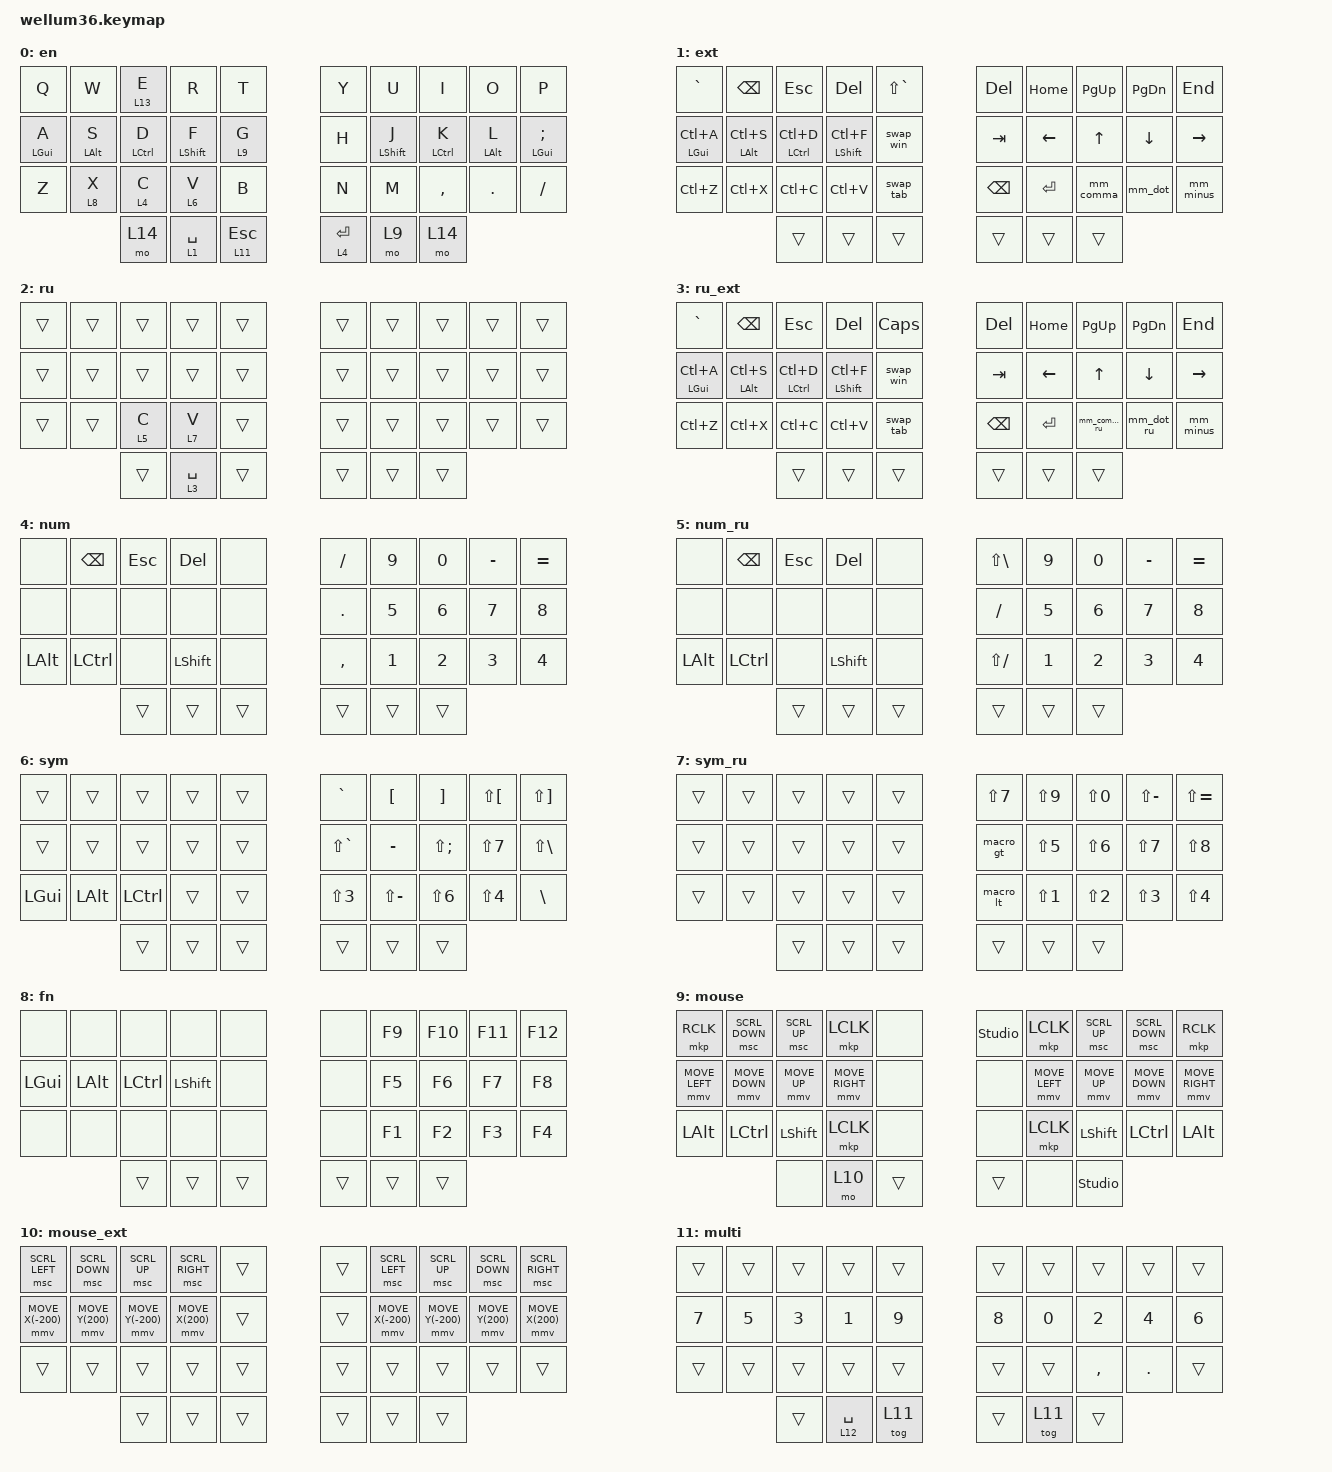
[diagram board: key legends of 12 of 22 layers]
#define ZMK_POINTING_DEFAULT_MOVE_VAL 1200  // default: 600
#define ZMK_POINTING_DEFAULT_SCRL_VAL 20    // default: 10

#include <behaviors/num_word.dtsi>
#include <behaviors.dtsi>
#include <dt-bindings/zmk/outputs.h>
#include <dt-bindings/zmk/keys.h>
#include <dt-bindings/zmk/bt.h>
#include <dt-bindings/zmk/pointing.h>

#include <dt-bindings/zmk/ext_power.h>

#define _ &kp
#define ___ &none
#define ______ &trans

#define DEF 0
#define GAM 1
#define GFN 2
#define NAV 3
#define SYM 4
#define NUM 5
#define CMD 6

#define MEH(key) LS(LC(LA(key)))

//#define SQT GRAVE
//#define DQT LS(GRAVE)
#define GRV RA(GRAVE)
#define PIP LS(BSLH)
#define BSL RA(BSLH)
#define NBSP RA(SPACE)

#define NSPC LC(LG(RIGHT))
#define PSPC LC(LG(LEFT))

// custom implementation of modified callum-mods,
// which can be released on second keypress
// and also work with swapper and/or tabber

#define PARAM_1 0
#define PARAM_2 0

#define MACRO(NAME, COMPATIBLE, BINDING_CELLS, BINDINGS) \
    NAME: NAME { \
        compatible = COMPATIBLE; \
        #binding-cells = <BINDING_CELLS>; \
        wait-ms = <0>; \
        tap-ms = <0>; \
        bindings = \
            <BINDINGS>; \
    };

#define MACRO_NO_PARAM(NAME, BINDINGS)  MACRO(NAME, "zmk,behavior-macro"          , 0, BINDINGS)
#define MACRO_ONE_PARAM(NAME, BINDINGS) MACRO(NAME, "zmk,behavior-macro-one-param", 1, BINDINGS)
#define MACRO_TWO_PARAM(NAME, BINDINGS) MACRO(NAME, "zmk,behavior-macro-two-param", 2, BINDINGS)

#define MAX_TIMER __UINT32_MAX__ // around 50 days

#define STICKY_FOREVER(NAME, BIND) \
    NAME: NAME { \
        compatible = "zmk,behavior-sticky-key"; \
        #binding-cells = <1>; \
        bindings = <BIND>; \
        release-after-ms = <MAX_TIMER>; \
        ignore-modifiers; \
    };

#define MODMORPH(NAME, NORMAL, MORPHED, MODS, KEEP_MODS) \
    NAME: NAME { \
        compatible = "zmk,behavior-mod-morph"; \
        #binding-cells = <0>; \
        bindings = <NORMAL>, <MORPHED>; \
        mods = <(MODS)>; \
        keep-mods = <(KEEP_MODS)>; \
    };

&sk {
        release-after-ms = <60000>;
};

/ {
    behaviors {
        MACRO_ONE_PARAM(
            m_release_key_twice,
            &macro_release
                &macro_param_1to1 &kp PARAM_1
                &macro_param_1to1 &kp PARAM_1
        )


        MACRO_ONE_PARAM(
            m_press_key_twice,
            &macro_press
                &macro_param_1to1 &kp PARAM_1
                &macro_param_1to1 &kp PARAM_1
            &macro_pause_for_release
            &macro_tap
                &m_release_key_twice PARAM_1
        )

        STICKY_FOREVER(sticky_forever, &m_press_key_twice)

        MODMORPH(
            cm_gui,
            &sticky_forever LGUI,
            &m_release_key_twice LGUI,
            MOD_LGUI,
            MOD_LGUI
        )

        MODMORPH(
            cm_alt,
            &sticky_forever LALT,
            &m_release_key_twice LALT,
            MOD_LALT,
            MOD_LALT
        )

        MODMORPH(
            cm_ctrl,
            &sticky_forever LCTRL,
            &m_release_key_twice LCTRL,
            MOD_LCTL,
            MOD_LCTL
        )

        MODMORPH(
            cm_sft,
            &sticky_forever LSHIFT,
            &m_release_key_twice LSHIFT,
            MOD_LSFT,
            MOD_LSFT
        )

        MACRO_TWO_PARAM(
            m_hold_mod_press_key,
            &macro_press
                &macro_param_1to1 &kp PARAM_1
            &macro_tap
                &macro_param_2to1 &kp PARAM_2
        )

        MODMORPH(
            tabber,
            &m_hold_mod_press_key LCTRL TAB,
            &kp TAB,
            MOD_LCTL,
            MOD_LCTL
        )

        MODMORPH(
            swapper_win,
            &m_hold_mod_press_key LALT TAB,
            &kp TAB,
            MOD_LALT,
            MOD_LALT
        )

        MODMORPH(
            swapper_mac,
            &m_hold_mod_press_key LGUI TAB,
            &kp TAB,
            MOD_LGUI,
            MOD_LGUI
        )

        MACRO_ONE_PARAM(
            la,
            &macro_tap
                &kp 0 // do nothing, fire all sticky keys
            &macro_press
                &macro_param_1to1 &mo PARAM_1
            &macro_pause_for_release
            &macro_release
                &macro_param_1to1 &mo PARAM_1
                &kp LSHFT
                &kp LCTRL
                &kp LALT
                &kp LGUI
        )

        tp: tap_preferred {
            compatible = "zmk,behavior-hold-tap";
            label = "TAP_PREFERRED";
            #binding-cells = <2>;
            tapping-term-ms = <150>;
            quick-tap-ms = <0>;
            flavor = "tap-preferred";
            bindings = <&kp>, <&kp>;
        };

        hml: home_row_mod_left {
            compatible = "zmk,behavior-hold-tap";
            #binding-cells = <2>;
            flavor = "balanced";
            require-prior-idle-ms = <150>;
            tapping-term-ms = <280>;
            quick-tap-ms = <175>;
            bindings = <&kp>, <&kp>;

            hold-trigger-key-positions = <5 6 7 8 9 9 15 16 18 19 26 27 28 29 35 36 37 17 5 6 7 8 9 15 16 17 18 19 25 26 27 28 29 32 33>;
            hold-trigger-on-release;
        };

        hmr: home_row_mod_right {
            compatible = "zmk,behavior-hold-tap";
            #binding-cells = <2>;
            flavor = "balanced";
            require-prior-idle-ms = <150>;
            tapping-term-ms = <280>;
            quick-tap-ms = <175>;
            bindings = <&kp>, <&kp>;

            hold-trigger-key-positions = <20 21 0 10 22 11 1 2 12 23 3 4 13 14 24 24 34 30 31>;
            hold-trigger-on-release;
        };

        num_word: num_word {
            compatible = "zmk,behavior-auto-layer";
            #binding-cells = <1>;
            continue-list = <BSPC DEL DOT COMMA PLUS MINUS STAR FSLH EQUAL>;
            ignore-numbers;
        };

        mm_comma: mm_comma {
            compatible = "zmk,behavior-mod-morph";
            label = "MM_COMMA";
            bindings = <&macro_comma>, <&kp SEMI>;

            #binding-cells = <0>;
            mods = <(MOD_LSFT|MOD_RSFT)>;
        };

        mm_comma_ru: mm_comma_ru {
            compatible = "zmk,behavior-mod-morph";
            label = "MM_COMMA_RU";
            bindings = <&macro_comma_ru>, <&kp LS(N4)>;

            #binding-cells = <0>;
            mods = <(MOD_LSFT|MOD_RSFT)>;
        };

        mm_dot: mm_dot {
            compatible = "zmk,behavior-mod-morph";
            label = "MM_DOT";
            bindings = <&macro_dot>, <&kp LS(SEMI)>;

            #binding-cells = <0>;
            mods = <(MOD_LSFT|MOD_RSFT)>;
        };

        mm_dot_ru: mm_dot_ru {
            compatible = "zmk,behavior-mod-morph";
            label = "MM_DOT_RU";
            bindings = <&macro_dot_ru>, <&kp LS(N6)>;

            #binding-cells = <0>;
            mods = <(MOD_LSFT|MOD_RSFT)>;
        };

        mm_minus: mm_minus {
            compatible = "zmk,behavior-mod-morph";
            label = "MM_MINUS";
            bindings = <&kp MINUS>, <&kp MINUS>;

            #binding-cells = <0>;
            mods = <(MOD_LSFT|MOD_RSFT)>;
        };

        swap_win: swap_win {
            compatible = "zmk,behavior-tri-state";
            label = "SWAPPER_WIN";
            #binding-cells = <0>;
            bindings = <&kt LALT>, <&kp TAB>, <&kt LALT>;

            ignored-key-positions = <4 16 19 20 21 22>;
        };

        swap_tab: swap_tab {
            compatible = "zmk,behavior-tri-state";
            label = "SWAPPER_TAB";
            #binding-cells = <0>;
            bindings = <&kt LCTRL>, <&kp TAB>, <&kt LCTRL>;

            ignored-key-positions = <4 16 19 20 21 22>;
        };
    };

    macros {
        macro_comma: macro_comma {
            compatible = "zmk,behavior-macro";
            #binding-cells = <0>;
            bindings = <&kp COMMA &kp SPACE>;
            label = "MACRO_COMMA";
        };

        macro_comma_ru: macro_comma_ru {
            compatible = "zmk,behavior-macro";
            #binding-cells = <0>;
            bindings = <&kp LS(SLASH) &kp SPACE>;
            label = "MACRO_COMMA_RU";
        };

        macro_dot: macro_dot {
            compatible = "zmk,behavior-macro";
            #binding-cells = <0>;
            bindings = <&kp DOT &kp SPACE &sk LSHFT>;
            label = "MACRO_DOT";
        };

        macro_dot_ru: macro_dot_ru {
            compatible = "zmk,behavior-macro";
            #binding-cells = <0>;
            bindings = <&kp SLASH &kp SPACE &sk LSHFT>;
            label = "MACRO_DOT_RU";
        };

        macro_lng: macro_lng {
            compatible = "zmk,behavior-macro";
            #binding-cells = <0>;
            bindings = <&kp CAPS &tog 2>;
            label = "MACRO_LNG";
        };

        macro_lng_en: macro_lng_sync {
            compatible = "zmk,behavior-macro";
            #binding-cells = <0>;
            bindings = <&kp CAPS &to 0>;
            label = "MACRO_LNG_SYNC";
        };

        macro_lt: macro_lt {
            compatible = "zmk,behavior-macro";
            #binding-cells = <0>;
            bindings = <&kp CAPS &kp LS(COMMA) &kp CAPS>;
            label = "MACRO_LT";
        };

        macro_gt: macro_gt {
            compatible = "zmk,behavior-macro";
            #binding-cells = <0>;
            bindings = <&kp CAPS &kp LS(DOT) &kp CAPS>;
            label = "MACRO_GT";
        };
    };

    combos {
        compatible = "zmk,combos";

        combo_lng_l {
            bindings = <&macro_lng>;
            key-positions = <3 13>;
        };

        combo_lng_r {
            bindings = <&macro_lng>;
            key-positions = <6 16>;
        };

        combo_esc {
            bindings = <&kp ESC>;
            key-positions = <2 12>;
        };

        combo_ret {
            bindings = <&kp RET>;
            key-positions = <16 26>;
        };

        combo_tab {
            bindings = <&kp TAB>;
            key-positions = <15 16>;
        };

        combo_spc {
            bindings = <&kp SPACE>;
            key-positions = <13 23>;
        };

        combo_num_word_en {
            bindings = <&num_word 4>;
            key-positions = <7 17>;
            layers = <0>;
        };

        combo_caps_word {
            bindings = <&caps_word>;
            key-positions = <8 18>;
        };

        combo_ins {
            bindings = <&kp INS>;
            key-positions = <15 25>;
        };

        combo_mouse_l {
            bindings = <&tog 9>;
            key-positions = <4 3>;
            layers = <1 3 9 10>;
        };

        combo_mouse_r {
            bindings = <&tog 9>;
            key-positions = <6 5>;
            layers = <1 3 9 10>;
        };

        combo_num_word_ru {
            bindings = <&num_word 5>;
            key-positions = <7 17>;
            layers = <2>;
        };

        combo_lbkt {
            bindings = <&kp LBKT>;
            key-positions = <9 8>;
        };

        combo_sqt {
            bindings = <&kp SQT>;
            key-positions = <18 19>;
        };

        combo_rbkt {
            bindings = <&kp RBKT>;
            key-positions = <34 29 28>;
        };

        combo_caps {
            bindings = <&kp CAPS>;
            key-positions = <5 15>;
        };

        combo_bootloader_left {
            bindings = <&bootloader>;
            key-positions = <0 24>;
            layers = <0>;
        };

        combo_bootloader_right {
            bindings = <&bootloader>;
            key-positions = <25 9>;
            layers = <0>;
        };
    };

    conditional_layers {
        compatible = "zmk,conditional-layers";
        tri_layer {
            if-layers  = <NAV SYM>;
            then-layer = <NUM>;
        };
    };
};

/ {
    keymap {
        compatible = "zmk,keymap";

        // LAYER 0
        en {
            // -----------------------------------------------------------------------------------------
            // | TAB  |  Q  |  W  |  E  |  R  |    T    |   |  Y  |  U   |  I  |  O  |  P  | ESC |
            // | CTRL |  A  |  S  |  D  |  F  |    G    |   |  H  |  J   |  K  |  L  |  ;  |  LWR/'   |
            // | SHFT |  Z  |  X  |  C  |  V  |    B    |   |  N  |  M   |  ,  |  .  |  /  | SHFT |
            //                    | GUI | LWR | ALT/ENT |   | HYPER/SPC | BKSP  | RSE |

            bindings = <
        &kp Q        &kp W        &lt 13 E      &kp R         &kp T         &kp Y        &kp U         &kp I         &kp O        &kp P
        &hml LGUI A  &hml LALT S  &hml LCTRL D  &hml LSHFT F  &lt 9 G       &kp H        &hmr LSHFT J  &hmr LCTRL K  &hmr LALT L  &hmr LGUI SEMI
        &kp Z        &lt 8 X      &lt 4 C       &lt 6 V       &kp B         &kp N        &kp M         &kp COMMA     &kp DOT      &kp FSLH
                                 &mo 14        &lt 1 SPACE   &lt 11 ESC    &lt 4 ENTER  &mo 9         &mo 14
            >;
        };

        // LAYER 1
        ext {
            bindings = <
        &kp GRAVE           &kp BACKSPACE   &kp ESCAPE       &kp DEL          &kp LS(GRAVE)    &kp DELETE     &kp HOME  &kp PG_UP  &kp PG_DN  &kp END
        &tp LEFT_GUI LC(A)  &tp LALT LC(S)  &tp LCTRL LC(D)  &tp LSHFT LC(F)  &swap_win        &kp TAB        &kp LEFT  &kp UP     &kp DOWN   &kp RIGHT
        &kp LC(Z)           &kp LC(X)       &kp LC(C)        &kp LC(V)        &swap_tab        &kp BACKSPACE  &kp RET   &mm_comma  &mm_dot    &mm_minus
                                           &trans           &trans           &trans           &trans         &trans    &trans
            >;
        };

        // LAYER 2
        ru {
            bindings = <
        &trans  &trans  &trans   &trans       &trans    &trans  &trans  &trans  &trans  &trans
        &trans  &trans  &trans   &trans       &trans    &trans  &trans  &trans  &trans  &trans
        &trans  &trans  &lt 5 C  &lt 7 V      &trans    &trans  &trans  &trans  &trans  &trans
                        &trans   &lt 3 SPACE  &trans    &trans  &trans  &trans
            >;
        };

        // LAYER 3
        ru_ext {
            bindings = <
        &kp GRAVE           &kp BACKSPACE   &kp ESCAPE       &kp DEL          &kp CAPS     &kp DEL        &kp HOME  &kp PG_UP     &kp PG_DN   &kp END
        &tp LEFT_GUI LC(A)  &tp LALT LC(S)  &tp LCTRL LC(D)  &tp LSHFT LC(F)  &swap_win    &kp TAB        &kp LEFT  &kp UP        &kp DOWN    &kp RIGHT
        &kp LC(Z)           &kp LC(X)       &kp LC(C)        &kp LC(V)        &swap_tab    &kp BACKSPACE  &kp RET   &mm_comma_ru  &mm_dot_ru  &mm_minus
                                           &trans           &trans           &trans       &trans         &trans    &trans
            >;
        };

        // LAYER 4
        num {
            bindings = <
        &none     &kp BACKSPACE  &kp ESC  &kp DEL    &none     &kp SLASH   &kp N9  &kp N0  &kp MINUS  &kp EQUAL
        &none     &none          &none    &none      &none     &kp PERIOD  &kp N5  &kp N6  &kp N7     &kp N8
        &kp LALT  &kp LCTRL      &none    &kp LSHFT  &none     &kp COMMA   &kp N1  &kp N2  &kp N3     &kp N4
                                 &trans   &trans     &trans    &trans      &trans  &trans
            >;
        };

        // LAYER 5
        num_ru {
            bindings = <
        &none     &kp BACKSPACE  &kp ESC  &kp DEL    &none     &kp LS(BACKSLASH)  &kp N9  &kp N0  &kp MINUS  &kp EQUAL
        &none     &none          &none    &none      &none     &kp SLASH          &kp N5  &kp N6  &kp N7     &kp N8
        &kp LALT  &kp LCTRL      &none    &kp LSHFT  &none     &kp LS(SLASH)      &kp N1  &kp N2  &kp N3     &kp N4
                                 &trans   &trans     &trans    &trans             &trans  &trans
            >;
        };

        // LAYER 6
        sym {
            bindings = <
        &trans    &trans    &trans     &trans  &trans    &kp GRAVE      &kp LEFT_BRACKET  &kp RIGHT_BRACKET  &kp LS(LEFT_BRACKET)  &kp LS(RIGHT_BRACKET)
        &trans    &trans    &trans     &trans  &trans    &kp LS(GRAVE)  &kp MINUS         &kp LS(SEMI)       &kp LS(N7)            &kp LS(BACKSLASH)
        &kp LGUI  &kp LALT  &kp LCTRL  &trans  &trans    &kp LS(N3)     &kp LS(MINUS)     &kp LS(NUMBER_6)   &kp LS(NUMBER_4)      &kp BACKSLASH
                            &trans     &trans  &trans    &trans         &trans            &trans
            >;
        };

        // LAYER 7
        sym_ru {
            bindings = <
        &trans  &trans  &trans  &trans  &trans    &kp LS(N7)  &kp LS(N9)  &kp LS(N0)  &kp LS(MINUS)  &kp LS(EQUAL)
        &trans  &trans  &trans  &trans  &trans    &macro_gt   &kp LS(N5)  &kp LS(N6)  &kp LS(N7)     &kp LS(N8)
        &trans  &trans  &trans  &trans  &trans    &macro_lt   &kp LS(N1)  &kp LS(N2)  &kp LS(N3)     &kp LS(N4)
                        &trans  &trans  &trans    &trans      &trans      &trans
            >;
        };

        // LAYER 8
        fn {
            bindings = <
        &none     &none     &none      &none      &none     &none   &kp F9  &kp F10  &kp F11  &kp F12
        &kp LGUI  &kp LALT  &kp LCTRL  &kp LSHFT  &none     &none   &kp F5  &kp F6   &kp F7   &kp F8
        &none     &none     &none      &none      &none     &none   &kp F1  &kp F2   &kp F3   &kp F4
                           &trans     &trans     &trans    &trans  &trans  &trans
            >;
        };

        // LAYER 9
        mouse {
            bindings = <
        &mkp RCLK       &msc SCRL_DOWN  &msc SCRL_UP  &mkp LCLK        &none     &studio_unlock  &mkp LCLK       &msc SCRL_UP    &msc SCRL_DOWN  &mkp RCLK
        &mmv MOVE_LEFT  &mmv MOVE_DOWN  &mmv MOVE_UP  &mmv MOVE_RIGHT  &none     &none           &mmv MOVE_LEFT  &mmv MOVE_UP    &mmv MOVE_DOWN  &mmv MOVE_RIGHT
        &kp LALT        &kp LCTRL       &kp LSHFT     &mkp LCLK        &none     &none           &mkp LCLK       &kp LSHFT       &kp LCTRL       &kp LALT
                                        &none         &mo 10           &trans    &trans          &none           &studio_unlock
            >;
        };

        // LAYER 10
        mouse_ext {
            bindings = <
        &msc SCRL_LEFT     &msc SCRL_DOWN    &msc SCRL_UP       &msc SCRL_RIGHT   &trans    &trans  &msc SCRL_LEFT     &msc SCRL_UP       &msc SCRL_DOWN    &msc SCRL_RIGHT
        &mmv MOVE_X(-200)  &mmv MOVE_Y(200)  &mmv MOVE_Y(-200)  &mmv MOVE_X(200)  &trans    &trans  &mmv MOVE_X(-200)  &mmv MOVE_Y(-200)  &mmv MOVE_Y(200)  &mmv MOVE_X(200)
        &trans             &trans            &trans             &trans            &trans    &trans  &trans             &trans             &trans            &trans
                                             &trans             &trans            &trans    &trans  &trans             &trans
            >;
        };

        // LAYER 11
        multi {
            bindings = <
        &trans  &trans  &trans  &trans        &trans     &trans  &trans   &trans     &trans   &trans
        &kp N7  &kp N5  &kp N3  &kp N1        &kp N9     &kp N8  &kp N0   &kp N2     &kp N4   &kp N6
        &trans  &trans  &trans  &trans        &trans     &trans  &trans   &kp COMMA  &kp DOT  &trans
                        &trans  &lt 12 SPACE  &tog 11    &trans  &tog 11  &trans
            >;
        };

        // LAYER 12
        multi_ext {
            bindings = <
        &none         &kp BACKSPACE  &tog 11    &kp DEL    &none        &kp BACKSPACE  &kp HOME  &kp PG_UP     &kp PG_DN   &kp END
        &sk LEFT_GUI  &sk LALT       &sk LCTRL  &sk LSHFT  &kp SPACE    &kp TAB        &kp LEFT  &kp UP        &kp DOWN    &kp RIGHT
        &none         &none          &none      &none      &kp DEL      &kp BACKSPACE  &kp RET   &mm_comma_ru  &mm_dot_ru  &mm_minus
                                       &trans     &trans     &trans       &trans         &trans    &trans
            >;
        };

        // LAYER 13
        app {
            bindings = <
        &trans  &trans  &trans  &trans  &trans    &trans  &trans  &trans  &trans  &trans
        &trans  &trans  &trans  &trans  &trans    &trans  &trans  &trans  &trans  &trans
        &trans  &trans  &trans  &trans  &trans    &trans  &trans  &trans  &trans  &trans
                        &trans  &trans  &trans    &trans  &trans  &trans
            >;
        };

        // LAYER 14
        sys {
            bindings = <
        &bootloader  &trans  &trans  &trans  &trans    &trans  &trans  &trans  &trans  &bootloader
        &trans       &trans  &trans  &trans  &trans    &trans  &trans  &trans  &trans  &trans
        &trans       &trans  &trans  &trans  &trans    &trans  &trans  &trans  &trans  &trans
                             &trans  &trans  &trans    &trans  &trans  &trans
            >;
        };

        def_layer {
            bindings = <
_ Q          _ W          _ E          _ R         _ T             _ Y          _ U          _ I          _ O          _ P
_ A          _ S          _ D          _ F         _ G             _ H          _ J          _ K          _ L          _ SEMI
_ Z          _ X          _ C          _ V         _ B             _ N          _ M          _ COMMA      _ DOT        _ FSLH
                          _ CAPS       _ SPACE     &la NAV         &la SYM      _ LSFT       _ RALT
            >;
        };

        gam_layer {
            bindings = <
_ TAB        _ Q          _ W          _ E         _ R             ___          ___          _ UP         ___          _ TAB
_ LSFT       _ A          _ S          _ D         _ F             ___          _ LEFT       _ DOWN       _ RIGHT      _ RSFT
_ LCTRL      _ Z          _ X          _ C         _ V             ___          ___          ___          ___          _ RCTRL
                          _ LALT       _ SPACE     &mo GFN         &tog GAM     _ SPACE      ______
            >;
        };

        gfn_layer {
            bindings = <
_ N5         _ N1         _ N2         _ N3        _ N4            &out OUT_TOG &bt BT_SEL 0 &bt BT_SEL 1 &bt BT_SEL 2 &bt BT_CLR_ALL
_ N0         _ N6         _ N7         _ N8        _ N9            ___          ___          ___          ___          ___
_ G          _ J          _ I          _ M         _ T             _ KP_NUM     ___          ___          &sys_reset   &bootloader
                          _ ESC        _ RET       ______          ______       ______       ___
            >;
        };

        nav_layer {
            bindings = <
&tabber      &swapper_win &swapper_mac ___         _ ESC           _ ESC        _ HOME       _ END        _ BSPC       _ DEL
&cm_gui      &cm_alt      &cm_ctrl     &cm_sft     _ RET           _ RET        _ LEFT       _ DOWN       _ UP         _ RIGHT
_ PSPC       _ NSPC       &tog GAM     _ PSCRN     _ TAB           _ TAB        _ PG_UP      _ PG_DN      _ APOS       _ KP_NUM
                          &mo CMD      ______      ______          ______       ______       ______
            >;
        };

        sym_layer {
            bindings = <
_ N1         _ N2         _ N3         _ N4        _ N5            _ N6         _ N7         _ N8         _ N9         _ N0
_ SEMI       _ GRV        _ SQT        _ DQT       _ MINUS         _ PLUS       &cm_sft      &cm_ctrl     &cm_alt      &cm_gui
_ BSL        ___          _ LS(LBKT)   _ LBKT      _ UNDER         _ EQUAL      _ RBKT       _ LS(RBKT)   _ PIP        _ BSLH
                          ______       ______      ______          ______       ______       _ RALT
            >;
        };

        num_layer {
            bindings = <
_ KP_N1      _ KP_N2      _ KP_N3      _ KP_N4     _ KP_N5         _ KP_N6      _ KP_N7      _ KP_N8      _ KP_N9      _ KP_N0
&cm_gui      &cm_alt      &cm_ctrl     &cm_sft     _ F11           _ F12        &cm_sft      &cm_ctrl     &cm_alt      &cm_gui
_ F1         _ F2         _ F3         _ F4        _ F5            _ F6         _ F7         _ F8         _ F9         _ F10
                          ______       ______      ______          ______       ______       ______
            >;
        };

        cmd_layer {
            bindings = <
_ MEH(Q)     _ MEH(W)     _ MEH(E)     _ MEH(R)    _ MEH(T)        _ MEH(Y)     _ C_VOL_DN   _ C_MUTE     _ C_VOL_UP   _ MEH(P)
_ MEH(A)     _ MEH(S)     _ MEH(D)     _ MEH(F)    _ MEH(G)        _ MEH(H)     _ C_PREV     _ C_PP       _ C_NEXT     _ MEH(SEMI)
&bootloader  _ MEH(X)     _ MEH(C)     _ MEH(V)    _ MEH(B)        _ MEH(N)     _ MEH(M)     _ MEH(COMMA) _ MEH(DOT)   &bootloader
                          ______       ______      ______          ______       ______       ______
            >;
        };
    };
};
